# PIC32MM0032GPL020 register map
Vendor: Microchip
Registers are 32-bit, read-write, reset 0x0 unless marked. A register's access mark holds for its fields unless they carry their own. Addresses are absolute, and some are shared; only a register's first bit layout is shown; [hi:lo] are bit positions; {n}, {i} and the like mark numbered series.

## PORTA
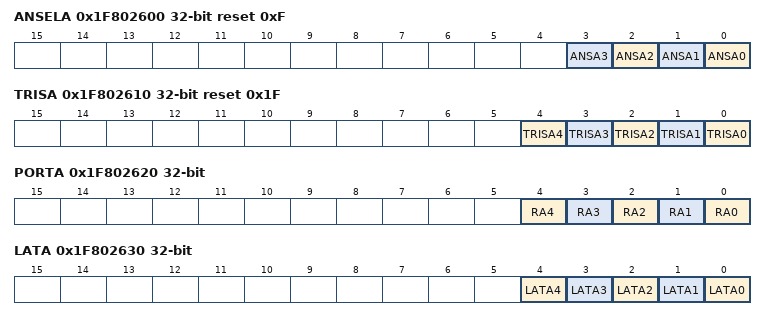
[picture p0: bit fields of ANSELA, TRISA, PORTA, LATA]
0x1F802600 ANSELA reset 0xF
  [n] ANSA{n} (n=0..3)
0x1F802610 TRISA reset 0x1F
  [n] TRISA{n} (n=0..4)
0x1F802620 PORTA reset not defined — (power-on value ---------------------------xxxxx)
  [n] RA{n} (n=0..4)
0x1F802630 LATA
  [n] LATA{n} (n=0..4)
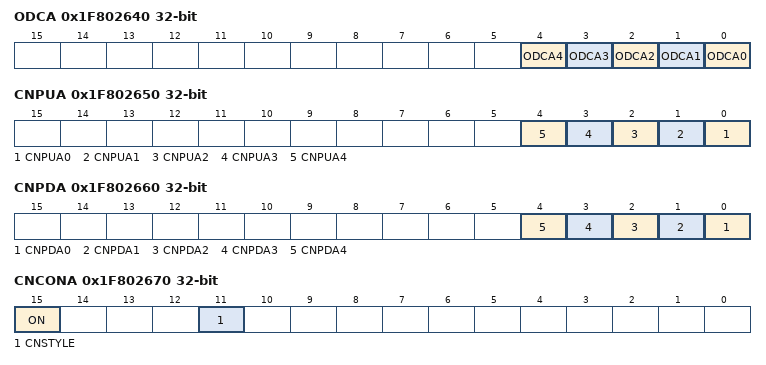
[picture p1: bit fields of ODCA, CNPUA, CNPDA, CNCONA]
0x1F802640 ODCA
  [n] ODCA{n} (n=0..4)
0x1F802650 CNPUA
  [n] CNPUA{n} (n=0..4)
0x1F802660 CNPDA
  [n] CNPDA{n} (n=0..4)
0x1F802670 CNCONA
  [15] ON, [11] CNSTYLE
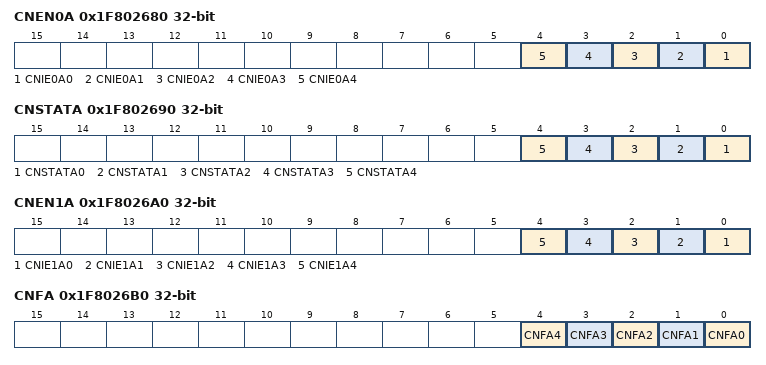
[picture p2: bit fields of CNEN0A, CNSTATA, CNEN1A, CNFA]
0x1F802680 CNEN0A
  [n] CNIE0A{n} (n=0..4)
0x1F802690 CNSTATA reset not defined — (power-on value ---------------------------xxxxx)
  [n] CNSTATA{n} (n=0..4)
0x1F8026A0 CNEN1A
  [n] CNIE1A{n} (n=0..4)
0x1F8026B0 CNFA
  [n] CNFA{n} (n=0..4)

## PORTB
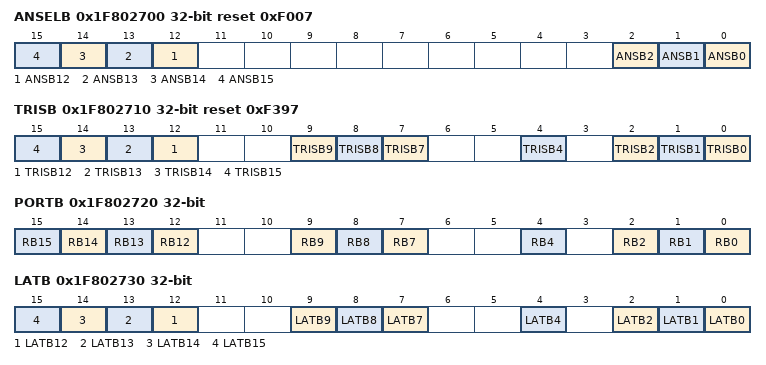
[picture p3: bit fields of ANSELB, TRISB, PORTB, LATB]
0x1F802700 ANSELB reset 0xF007
  [n] ANSB{n} (n=12..15), [2] ANSB2, [1] ANSB1, [0] ANSB0
0x1F802710 TRISB reset 0xF397
  [n] TRISB{n} (n=12..15), [9] TRISB9, [8] TRISB8, [7] TRISB7, [4] TRISB4, [2] TRISB2, [1] TRISB1, [0] TRISB0
0x1F802720 PORTB reset not defined — (power-on value ----------------xxxx--xxx--x-xxx)
  [n] RB{n} (n=12..15), [9] RB9, [8] RB8, [7] RB7, [4] RB4, [2] RB2, [1] RB1, [0] RB0
0x1F802730 LATB
  [n] LATB{n} (n=12..15), [9] LATB9, [8] LATB8, [7] LATB7, [4] LATB4, [2] LATB2, [1] LATB1, [0] LATB0
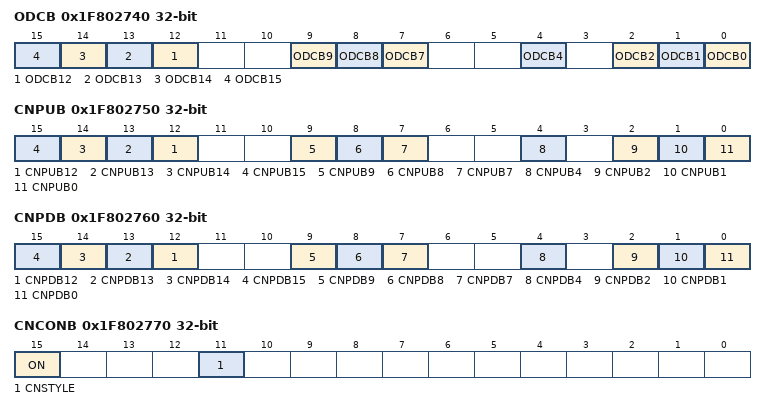
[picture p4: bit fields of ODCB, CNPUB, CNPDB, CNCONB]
0x1F802740 ODCB
  [n] ODCB{n} (n=12..15), [9] ODCB9, [8] ODCB8, [7] ODCB7, [4] ODCB4, [2] ODCB2, [1] ODCB1, [0] ODCB0
0x1F802750 CNPUB
  [n] CNPUB{n} (n=12..15), [9] CNPUB9, [8] CNPUB8, [7] CNPUB7, [4] CNPUB4, [2] CNPUB2, [1] CNPUB1, [0] CNPUB0
0x1F802760 CNPDB
  [n] CNPDB{n} (n=12..15), [9] CNPDB9, [8] CNPDB8, [7] CNPDB7, [4] CNPDB4, [2] CNPDB2, [1] CNPDB1, [0] CNPDB0
0x1F802770 CNCONB
  [15] ON, [11] CNSTYLE
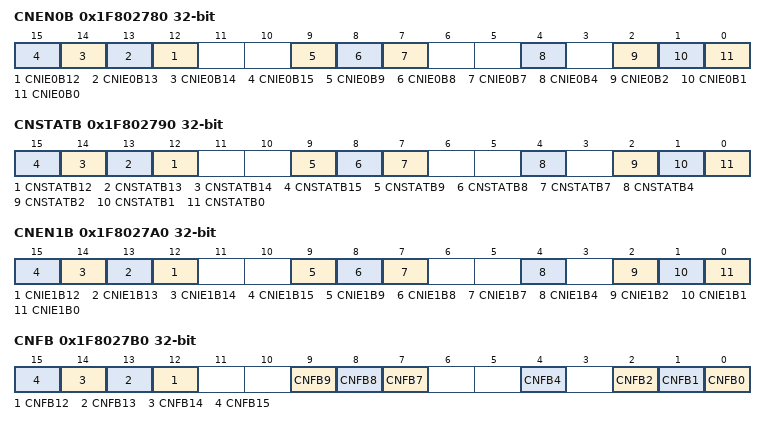
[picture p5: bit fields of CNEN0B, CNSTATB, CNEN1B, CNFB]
0x1F802780 CNEN0B
  [n] CNIE0B{n} (n=12..15), [9] CNIE0B9, [8] CNIE0B8, [7] CNIE0B7, [4] CNIE0B4, [2] CNIE0B2, [1] CNIE0B1, [0] CNIE0B0
0x1F802790 CNSTATB reset not defined — (power-on value ----------------xxxx--xxx--x-xxx)
  [n] CNSTATB{n} (n=12..15), [9] CNSTATB9, [8] CNSTATB8, [7] CNSTATB7, [4] CNSTATB4, [2] CNSTATB2, [1] CNSTATB1, [0] CNSTATB0
0x1F8027A0 CNEN1B
  [n] CNIE1B{n} (n=12..15), [9] CNIE1B9, [8] CNIE1B8, [7] CNIE1B7, [4] CNIE1B4, [2] CNIE1B2, [1] CNIE1B1, [0] CNIE1B0
0x1F8027B0 CNFB
  [n] CNFB{n} (n=12..15), [9] CNFB9, [8] CNFB8, [7] CNFB7, [4] CNFB4, [2] CNFB2, [1] CNFB1, [0] CNFB0

## WDT
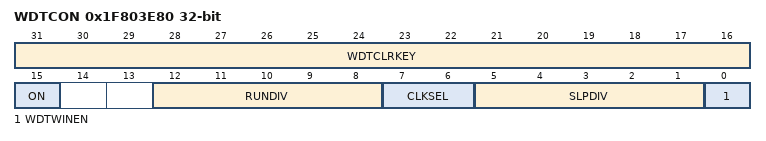
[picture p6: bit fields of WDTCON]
0x1F803E80 WDTCON reset not defined — (power-on value 0000000000000000x--xxxxxxxxxxxx0)
  [31:16] WDTCLRKEY wo, [15] ON, [12:8] RUNDIV ro, [7:6] CLKSEL ro, [5:1] SLPDIV ro, [0] WDTWINEN

## TMR1
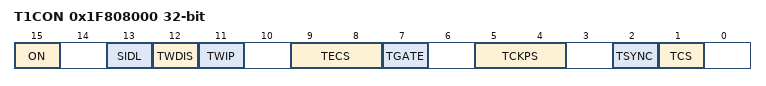
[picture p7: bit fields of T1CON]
0x1F808000 T1CON
  [15] ON, [13] SIDL, [12] TWDIS, [11] TWIP, [9:8] TECS, [7] TGATE, [5:4] TCKPS, [2] TSYNC, [1] TCS
0x1F808010 TMR1
0x1F808020 PR1 reset 0xFFFF

## SPI1
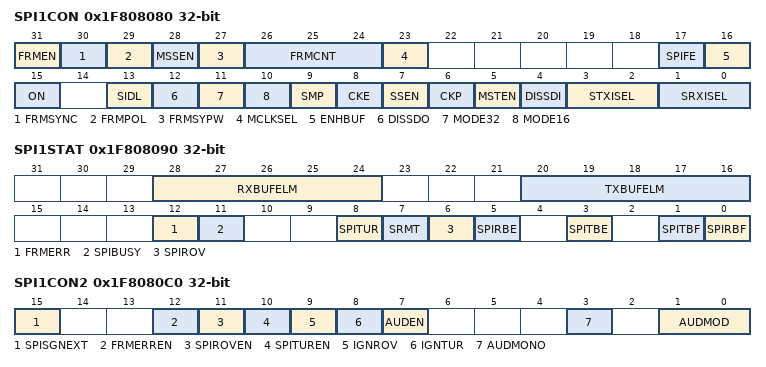
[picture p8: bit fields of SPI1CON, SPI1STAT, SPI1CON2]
0x1F808080 SPI1CON reset not defined — (power-on value 00000000x-----0000000000000x0000)
  [31] FRMEN, [30] FRMSYNC, [29] FRMPOL, [28] MSSEN, [27] FRMSYPW, [26:24] FRMCNT, [23] MCLKSEL, [17] SPIFE, [16] ENHBUF, [15] ON, [13] SIDL, [12] DISSDO, [11] MODE32, [10] MODE16, [9] SMP, [8] CKE, [7] SSEN, [6] CKP, [5] MSTEN, [4] DISSDI, [3:2] STXISEL, [1:0] SRXISEL
0x1F808090 SPI1STAT reset not defined — (power-on value ---00000---00000---x0--0000-0-00)
  [28:24] RXBUFELM ro, [20:16] TXBUFELM ro, [12] FRMERR, [11] SPIBUSY ro, [8] SPITUR ro, [7] SRMT ro, [6] SPIROV ro, [5] SPIRBE ro, [3] SPITBE ro, [1] SPITBF ro, [0] SPIRBF ro
0x1F8080A0 SPI1BUF reset not defined — (power-on value xxxxxxxxxxxxxxxxxxxxxxxxxxxxxxxx)
0x1F8080B0 SPI1BRG reset not defined — (power-on value -------------------xxxxxxxxxxxxx)
  [12:0] SPI1BRG
0x1F8080C0 SPI1CON2 reset not defined — (power-on value ----------------x--xxxxxx---x-xx)
  [15] SPISGNEXT, [12] FRMERREN, [11] SPIROVEN, [10] SPITUREN, [9] IGNROV, [8] IGNTUR, [7] AUDEN, [3] AUDMONO, [1:0] AUDMOD

## SPI2
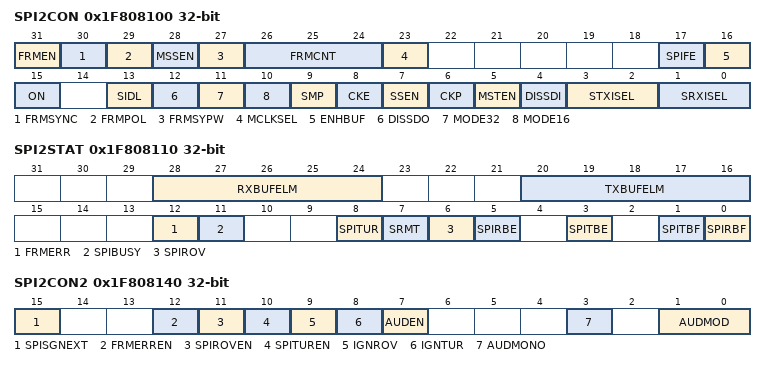
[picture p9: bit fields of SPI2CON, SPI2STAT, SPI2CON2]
0x1F808100 SPI2CON reset not defined — (power-on value 00000000x-----0000000000000x0000)
  [31] FRMEN, [30] FRMSYNC, [29] FRMPOL, [28] MSSEN, [27] FRMSYPW, [26:24] FRMCNT, [23] MCLKSEL, [17] SPIFE, [16] ENHBUF, [15] ON, [13] SIDL, [12] DISSDO, [11] MODE32, [10] MODE16, [9] SMP, [8] CKE, [7] SSEN, [6] CKP, [5] MSTEN, [4] DISSDI, [3:2] STXISEL, [1:0] SRXISEL
0x1F808110 SPI2STAT reset not defined — (power-on value ---00000---00000---x0--0000-0-00)
  [28:24] RXBUFELM ro, [20:16] TXBUFELM ro, [12] FRMERR, [11] SPIBUSY ro, [8] SPITUR ro, [7] SRMT ro, [6] SPIROV ro, [5] SPIRBE ro, [3] SPITBE ro, [1] SPITBF ro, [0] SPIRBF ro
0x1F808120 SPI2BUF reset not defined — (power-on value xxxxxxxxxxxxxxxxxxxxxxxxxxxxxxxx)
0x1F808130 SPI2BRG reset not defined — (power-on value -------------------xxxxxxxxxxxxx)
  [12:0] SPI2BRG
0x1F808140 SPI2CON2 reset not defined — (power-on value ----------------x--xxxxxx---x-xx)
  [15] SPISGNEXT, [12] FRMERREN, [11] SPIROVEN, [10] SPITUREN, [9] IGNROV, [8] IGNTUR, [7] AUDEN, [3] AUDMONO, [1:0] AUDMOD

## SABE_UDID
{0x1FC4183C+4i} UDID{i} ro reset not defined (i=1..5)
